# pse84_a0 register map
Vendor: Infineon Technologies; Series: PSE84_A0; File version: 1.0
CPU: CM33 r0p1, little endian, MPU, FPU, VTOR, 3 interrupt priority bits
Registers are 32-bit, read-write, reset 0x0 unless marked. A register's access mark holds for its fields unless they carry their own. Offsets are from the block's base; [hi:lo] are bit positions; {n}, {i} and the like mark numbered series; 'fields as' and 'values as' point back to an identical list.

## APPCPUSS — APPCPUSS registers
Base 0x441C0000
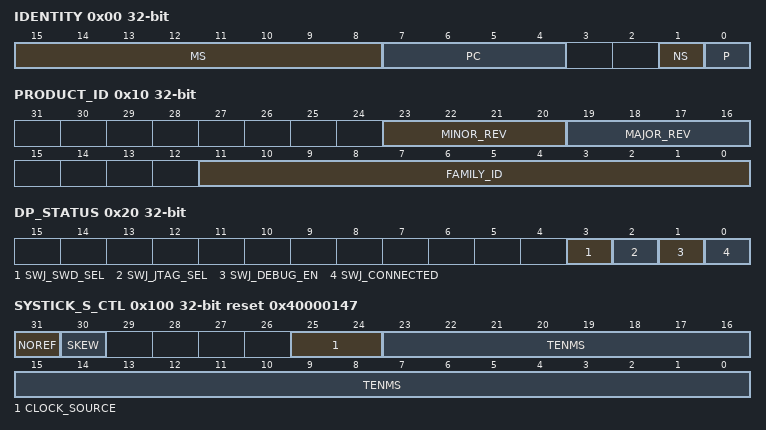
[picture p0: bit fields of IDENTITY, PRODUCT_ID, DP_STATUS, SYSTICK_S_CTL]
0x00 IDENTITY ro reset not defined
  [15:8] MS — This field specifies the bus master identifier of the transfer that reads the register.
  [7:4] PC — This field specifies the protection context of the transfer that reads the register.
  [1] NS — This field specifies the security setting ('0': secure mode; '1': non-secure mode) of the transfer that reads the register.
  [0] P — This field specifies the privileged setting ('0': user mode; '1': privileged mode) of the transfer that reads the register.
0x10 PRODUCT_ID ro (reset mask 0xFFF) — Product identifier and version (same as CoreSight RomTables)
  [23:20] MINOR_REV — Minor Revision, starts with 1, increments with metal layer only tape-out (implemented with metal ECO-able tie-off)
  [19:16] MAJOR_REV — Major Revision, starts with 1, increments with all layer tape-out (implemented with metal ECO-able tie-off)
  [11:0] FAMILY_ID — Family ID. Common ID for a product family.
0x20 DP_STATUS ro — Debug port status
  [3] SWJ_SWD_SEL — Specifies if the SWD interface is selected. '0': SWD not selected. '1': SWD selected.
  [2] SWJ_JTAG_SEL — Specifies if the JTAG interface is selected. '0': JTAG not selected. '1': JTAG selected.
  [1] SWJ_DEBUG_EN — Specifies if SWJ debug is enabled, i.e. CDBGPWRUPACK is '1' and thus debug clocks are on: '0': Disabled. '1': Enabled.
  [0] SWJ_CONNECTED — Specifies if the SWJ debug port is connected; i.e. debug host interface is active: '0': Not connected/not active. '1': Connected/active.
0x30 BUFF_CTL reset 0x1 — Buffer control
  [0] WRITE_BUFF — Specifies if write transfer can be buffered in the bus infrastructure bridges: '0': Write transfers are not buffered, independent of the transfer's bufferable attribute. '1': Write transfers can be buffered, if the transfer's bufferable attribute indicates that the transfer is a bufferable/posted write. This bit controls buffering only for subsystems that interfaced using the AHB2AHB bridge, not for components utilised from ARM.
0x50 INFRA_CTL — Infrastructure Control
  [0] CLOCK_FORCE — Force Infrastructure clock gating to be always ON. 0: Disabled 1: Enabled
0x100 SYSTICK_S_CTL reset 0x40000147 — Secure SysTick timer control
  [31] NOREF — Specifies if an external clock source is provided: '0': An external clock source is provided. '1': An external clock source is NOT provided and only the CPU internal clock can be used as SysTick timer clock source.
  [30] SKEW — Specifies the precision of the clock source and if the TENMS field represents exactly 10 ms (clock source frequency is a multiple of 100 Hz). This affects the suitability of the SysTick timer as a SW real-time clock: '0': Precise. '1': Imprecise.
  [25:24] CLOCK_SOURCE — Specifies an external clock source: '0': The low frequency clock 'clk_lf' is selected. The precision of this clock depends on whether the low frequency clock source is a SRSS internal RC oscillator (imprecise) or a device external crystal oscillator (precise). '1': The internal main oscillator (IMO) clock 'clk_imo' is selected. The MXS40 platform uses a fixed frequency IMO clock. o '2': The external crystal oscillator (ECO) clock 'clk_eco' is selected. '3': The SRSS 'clk_timer' is selected ('clk_timer' is a divided/gated version of 'clk_hf' or 'clk_imo'). Note: If NOREF is '1', the CLOCK_SOURCE value is NOT used. Note: It is SW's responsibility to provide the correct NOREF, SKEW and TENMS field values for the selected clock source.
  [23:0] TENMS — Specifies the number of clock source cycles (minus 1) that make up 10 ms. E.g., for a 32,768 Hz reference clock, TENMS is 328 - 1 = 327.
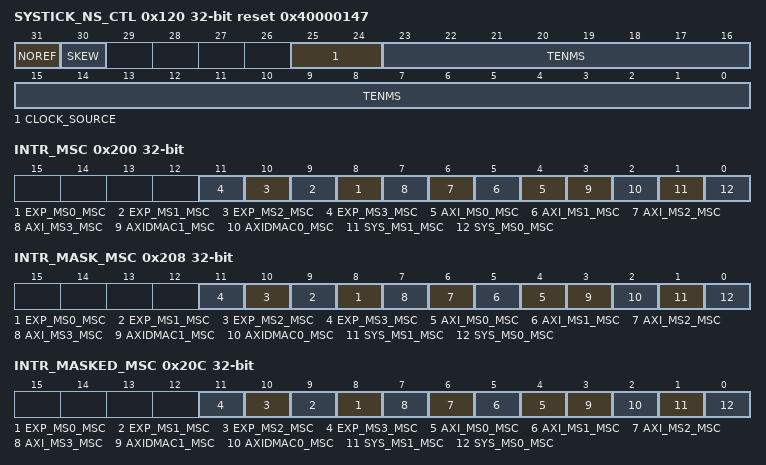
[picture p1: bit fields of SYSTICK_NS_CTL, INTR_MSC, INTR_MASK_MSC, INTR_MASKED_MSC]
0x120 SYSTICK_NS_CTL reset 0x40000147 — Non Secure SysTick timer control
  fields as SYSTICK_S_CTL
0x200 INTR_MSC — Master security controller Interrupt
  [n+8] EXP_MS{n}_MSC (n=0..3) — This interrupt cause field is activated (HW sets the field to '1') when there is a security violation on external AHB master {n} interface. SW writes a '1' to this field to clear the interrupt cause to '0'. The HW captures a new MSC interrupt only after clearing the interrupt cause.
  [n+4] AXI_MS{n}_MSC (n=0..3) — This interrupt cause field is activated (HW sets the field to '1') when there is a security violation on external AXI master {n} interface. SW writes a '1' to this field to clear the interrupt cause to '0'. The HW captures a new MSC interrupt only after clearing the interrupt cause.
  [3] AXIDMAC1_MSC — This interrupt cause field is activated (HW sets the field to '1') when there is a security violation on AXI DMA controller 1 interface. SW writes a '1' to this field to clear the interrupt cause to '0'. The HW captures a new MSC interrupt only after clearing the interrupt cause.
  [2] AXIDMAC0_MSC — This interrupt cause field is activated (HW sets the field to '1') when there is a security violation on AXI DMA controller 0 interface. SW writes a '1' to this field to clear the interrupt cause to '0'. The HW captures a new MSC interrupt only after clearing the interrupt cause.
  [1] SYS_MS1_MSC — This interrupt cause field is activated (HW sets the field to '1') when there is a security violation on APPCPUSS external SYS AHB5 bus master interface 1. SW writes a '1' to this field to clear the interrupt cause to '0'. The HW captures a new MSC interrupt only after clearing the interrupt cause.
  [0] SYS_MS0_MSC — This interrupt cause field is activated (HW sets the field to '1') when there is a security violation on APPCPUSS external SYS AHB5 bus master interface 0. SW writes a '1' to this field to clear the interrupt cause to '0'. The HW captures a new MSC interrupt only after clearing the interrupt cause.
0x208 INTR_MASK_MSC — Master security controller Interrupt mask
  [n+8] EXP_MS{n}_MSC (n=0..3) — Mask bit for the corresponding field in the APPCPUSS_INTR_MSC register.
  [n+4] AXI_MS{n}_MSC (n=0..3) — Mask bit for the corresponding field in the APPCPUSS_INTR_MSC register.
  [3] AXIDMAC1_MSC — Mask bit for the corresponding field in the APPCPUSS_INTR_MSC register.
  [2] AXIDMAC0_MSC — Mask bit for the corresponding field in the APPCPUSS_INTR_MSC register.
  [1] SYS_MS1_MSC — Mask bit for the corresponding field in the APPCPUSS_INTR_MSC register.
  [0] SYS_MS0_MSC — Mask bit for the corresponding field in the APPCPUSS_INTR_MSC register.
0x20C INTR_MASKED_MSC ro — Master security controller Interrupt masked
  [n+8] EXP_MS{n}_MSC (n=0..3) — Logical AND of corresponding APPCPUSS_INTR_MSC and APPCPUSS_INTR_MASK_MSC bit fields.
  [n+4] AXI_MS{n}_MSC (n=0..3) — Logical AND of corresponding APPCPUSS_INTR_MSC and APPCPUSS_INTR_MASK_MSC bit fields.
  [3] AXIDMAC1_MSC — Logical AND of corresponding APPCPUSS_INTR_MSC and APPCPUSS_INTR_MASK_MSC bit fields.
  [2] AXIDMAC0_MSC — Logical AND of corresponding APPCPUSS_INTR_MSC and APPCPUSS_INTR_MASK_MSC bit fields.
  [1] SYS_MS1_MSC — Logical AND of corresponding APPCPUSS_INTR_MSC and APPCPUSS_INTR_MASK_MSC bit fields.
  [0] SYS_MS0_MSC — Logical AND of corresponding APPCPUSS_INTR_MSC and APPCPUSS_INTR_MASK_MSC bit fields.
0x300 INTR_AHB2AXI — AHB to AXI Bridge Interrupt
  [0] BUFF_WRITE_ERR — Set to '1', when there is a buffered write error occurs in xhb500 ahb to axi bridge
0x304 INTR_SET_AHB2AXI — AHB to AXI Bridge Interrupt set
  [0] BUFF_WRITE_ERR — Write INTR_SET_AHB2AXI field with '1' to set corresponding INTR_AHB2AXI.BUFF_WRITE_ERR field (a write of '0' has no effect).
0x308 INTR_MASK_AHB2AXI — AHB to AXI Bridge Interrupt mask
  [0] BUFF_WRITE_ERR — Mask for corresponding field in INTR_AHB2AXI register.
0x30C INTR_MASKED_AHB2AXI ro — AHB to AXI Bridge Interrupt masked
  [0] BUFF_WRITE_ERR — Logical and of corresponding INTR_AHB2AXI and INTR_MASK_AHB2AXI fields.
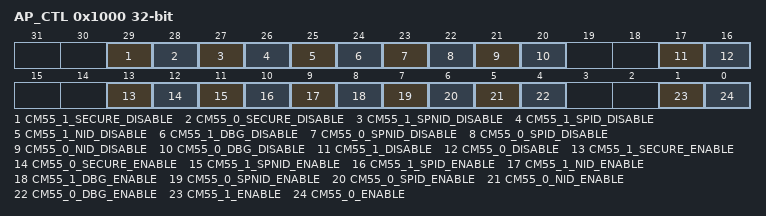
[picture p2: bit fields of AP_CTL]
0x1000 AP_CTL — Access port control
  [29] CM55_1_SECURE_DISABLE — Disables the CM55_1 secure AP interface: '0': Enabled. '1': Disabled. Typically, this field is set by the Cypress boot code with information from eFUSE. The access port is only enabled when CM55_DISABLE is '0' and CM55_ENABLE is '1'.
  [28] CM55_0_SECURE_DISABLE — Disables the CM55_0 secure AP interface: '0': Enabled. '1': Disabled. Typically, this field is set by the Cypress boot code with information from eFUSE. The access port is only enabled when CM0_DISABLE is '0' and CM0_ENABLE is '1'.
  [27] CM55_1_SPNID_DISABLE — Refer CM55_0_SPNID_DISABLE description.
  [26] CM55_1_SPID_DISABLE — Refer CM55_0_SPID_DISABLE description.
  [25] CM55_1_NID_DISABLE — Refer CM55_0_NID_DISABLE description.
  [24] CM55_1_DBG_DISABLE — Refer CM55_0_DBG_DISABLE description.
  [23] CM55_0_SPNID_DISABLE — Secure non-invasive debug disable for CM55_0. '1': Disables non-invasive debug features when the processor is in Secure state. '0': Enables non-invasive debug features when the processor is in Secure state. Typically, this field is set by the Cypress boot code with information from eFUSE. The non-invasive debug in secure state is only enabled when CM55_0_SPNID_DISABLE is '0' and CM55_0_SPNID_ENABLE is '1'.
  [22] CM55_0_SPID_DISABLE — Secure invasive debug disable for CM55_0. '1': disables all halt mode and invasive debug features when the processor is in Secure state. '0': Enables all halt mode and invasive debug features when the processor is in Secure state. Typically, this field is set by the Cypress boot code with information from eFUSE. The invasive debug in secure state is only enabled when CM55_0_SPID_DISABLE is '0' and CM55_0_SPID_ENABLE is '1'.
  [21] CM55_0_NID_DISABLE — Disable Non-invasive debug for CM55_0. '1': Disables all trace and non-invasive debug features. '0': Enables all trace and non-invasive debug features. Typically, this field is set by the Cypress boot code with information from eFUSE. The non-invasive debug is only enabled when CM55_0_NID_DISABLE is '0' and CM55_0_NID_ENABLE is '1'.
  [20] CM55_0_DBG_DISABLE — Disable Invasive debug for CM55_0. '1': Disables all halt-mode and invasive debug features. '0': Enables invasive debug features. Typically, this field is set by the Cypress boot code with information from eFUSE. The invasive debug is only enabled when CM55_0_DBG_DISABLE is '0' and CM55_0_DBG_ENABLE is '1'.
  [17] CM55_1_DISABLE — Disables the CM55_1 AP interface: '0': Enabled. '1': Disabled. Typically, this field is set by the Cypress boot code with information from eFUSE. The access port is only enabled when CM55_1_DISABLE is '0' and CM55_1_ENABLE is '1'.
  [16] CM55_0_DISABLE — Disables the CM55_0 AP interface: '0': Enabled. '1': Disabled. Typically, this field is set by the Cypress boot code with information from eFUSE. The access port is only enabled when CM55_0_DISABLE is '0' and CM55_0_ENABLE is '1'.
  [13] CM55_1_SECURE_ENABLE — Enables the CM55_1 secure AP interface: '0': Disabled. '1': Enabled.
  [12] CM55_0_SECURE_ENABLE — Enables the CM55_0 secure AP interface: '0': Disabled. '1': Enabled.
  [11] CM55_1_SPNID_ENABLE — Refer CM55_0_SPNID_ENABLE.
  [10] CM55_1_SPID_ENABLE — Refer CM55_0_SPID_ENABLE.
  [9] CM55_1_NID_ENABLE — Refer CM55_0_NID_ENABLE.
  [8] CM55_1_DBG_ENABLE — Refer CM55_0_DBG_ENABLE.
  [7] CM55_0_SPNID_ENABLE — Secure non-invasive debug enable for CM55_0. '0': Disables non-invasive debug features when the processor is in Secure state. '1': Enables non-invasive debug features when the processor is in Secure state.
  [6] CM55_0_SPID_ENABLE — Secure invasive debug enable for CM55_0. '0': disables all halt mode and invasive debug features when the processor is in Secure state. '1': Enables all halt mode and invasive debug features when the processor is in Secure state.
  [5] CM55_0_NID_ENABLE — Non-invasive debug enable for CM55_0. '0': Disables all trace and non-invasive debug features. '1': Enables all trace and non-invasive debug features.
  [4] CM55_0_DBG_ENABLE — Invasive debug enable for CM55_0. '0': Disables all halt-mode and invasive debug features. '1': Enables invasive debug features.
  [1] CM55_1_ENABLE — Enables the CM55_1 AP interface: '0': Disabled. '1': Enabled.
  [0] CM55_0_ENABLE — Enables the CM55_0 AP interface: '0': Disabled. '1': Enabled.
